# CH564 register map
Vendor: WCH Ltd.; File version: 1.1
Registers are 8-bit, read-write, reset 0x0 unless marked. A register's access mark holds for its fields unless they carry their own. Offsets are from the block's base; [hi:lo] are bit positions.

## UART0
Base 0x4040D000
0x00 R8_UART0_RBR_R8_UART0_THR_R8_UART0_DLL ro — UART0 receiver buffer, receiving byte / UART0 transmitter holding, transmittal byte/DLL is low-byte,DLM is high-byte,together they from the baud rate divisor register
  [7:0] R8_UART0_RBR__R8_UART0_THR_UART0_DLL — UART receiver buffer, receiving byte / UART transmitter holding, transmittal byte
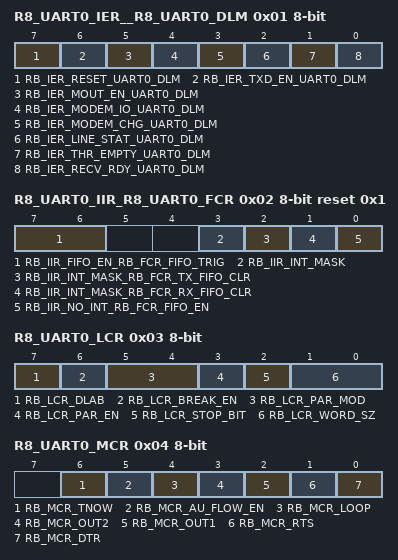
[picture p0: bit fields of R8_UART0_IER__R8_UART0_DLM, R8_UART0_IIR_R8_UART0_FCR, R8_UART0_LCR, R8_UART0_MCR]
0x01 R8_UART0_IER__R8_UART0_DLM — UART0 interrupt enable/baud rate divisor register, DLL is low-byte,DLM is high-byte,together they from the baud rate divisor register
  [7] RB_IER_RESET_UART0_DLM — UART software reset control, high action, auto clear
  [6] RB_IER_TXD_EN_UART0_DLM — UART TXD pin enable
  [5] RB_IER_MOUT_EN_UART0_DLM — UART0 RTS/DTR output pin enable
  [4] RB_IER_MODEM_IO_UART0_DLM — serial modem MODEM signal pin selection bit
  [3] RB_IER_MODEM_CHG_UART0_DLM — UART0 interrupt enable for modem status change
  [2] RB_IER_LINE_STAT_UART0_DLM — UART interrupt enable for receiver line status
  [1] RB_IER_THR_EMPTY_UART0_DLM — UART interrupt enable for THR empty
  [0] RB_IER_RECV_RDY_UART0_DLM — UART interrupt enable for receiver data ready
0x02 R8_UART0_IIR_R8_UART0_FCR ro reset 0x1 — UART0 interrupt identification/FIFO control register
  [7:6] RB_IIR_FIFO_EN_RB_FCR_FIFO_TRIG — UART FIFO enabled flag/UART receiver FIFO trigger level
  [3] RB_IIR_INT_MASK — UART interrupt flag bit mask
  [2] RB_IIR_INT_MASK_RB_FCR_TX_FIFO_CLR — UART interrupt flag bit mask/clear UART transmitter FIFO, high action, auto clear
  [1] RB_IIR_INT_MASK_RB_FCR_RX_FIFO_CLR — UART interrupt flag bit mask/clear UART receiver FIFO, high action, auto clear
  [0] RB_IIR_NO_INT_RB_FCR_FIFO_EN — UART interrupt status flag/FIFO enable bit
0x03 R8_UART0_LCR — UART0 line control
  [7] RB_LCR_DLAB — UART divisor latch access enable bit
  [6] RB_LCR_BREAK_EN — UART break control enable
  [5:4] RB_LCR_PAR_MOD — UART parity mode
  [3] RB_LCR_PAR_EN — UART parity enable
  [2] RB_LCR_STOP_BIT — UART stop bit length
  [1:0] RB_LCR_WORD_SZ — UART word bit length
0x04 R8_UART0_MCR — UART0 modem control
  [6] RB_MCR_TNOW — UART0 enable TNOW output on DTR pin
  [5] RB_MCR_AU_FLOW_EN — UART0 enable autoflow control
  [4] RB_MCR_LOOP — UART0 enable local loop back
  [3] RB_MCR_OUT2 — UART interrupt required output control
  [2] RB_MCR_OUT1 — UART0 MODEM Control bit
  [1] RB_MCR_RTS — UART0 control RTS output
  [0] RB_MCR_DTR — UART0 control DTR output
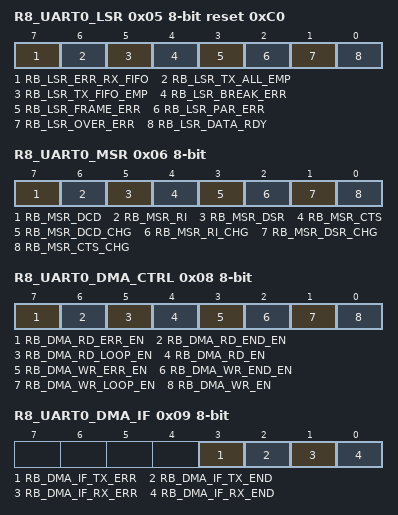
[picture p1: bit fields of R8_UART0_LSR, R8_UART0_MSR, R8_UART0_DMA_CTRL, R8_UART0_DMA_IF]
0x05 R8_UART0_LSR ro reset 0xC0 — UART0 line status
  [7] RB_LSR_ERR_RX_FIFO — indicate error in UART receiver fifo
  [6] RB_LSR_TX_ALL_EMP — UART transmitter all empty status
  [5] RB_LSR_TX_FIFO_EMP — UART transmitter fifo empty status
  [4] RB_LSR_BREAK_ERR — UART receiver break error
  [3] RB_LSR_FRAME_ERR — UART receiver frame error
  [2] RB_LSR_PAR_ERR — UART receiver frame error
  [1] RB_LSR_OVER_ERR — UART receiver overrun error
  [0] RB_LSR_DATA_RDY — UART receiver fifo data ready status
0x06 R8_UART0_MSR ro — UART0 modem status
  [7] RB_MSR_DCD — UART0 DCD action status
  [6] RB_MSR_RI — UART0 RI action status
  [5] RB_MSR_DSR — UART0 DSR action status
  [4] RB_MSR_CTS — UART0 CTS action status
  [3] RB_MSR_DCD_CHG — UART0 DCD changed status, high action
  [2] RB_MSR_RI_CHG — UART0 RI changed status, high action
  [1] RB_MSR_DSR_CHG — UART0 DSR changed status, high action
  [0] RB_MSR_CTS_CHG — UART0 CTS changed status, high action
0x07 R8_UART0_DIV — UART0 pre-frequency divisiono register
  [7:0] UART0_DIV — System clock is pre-divided after frequency doubling to generate the internal reference clock of the serial port
0x08 R8_UART0_DMA_CTRL — DMA Control register
  [7] RB_DMA_RD_ERR_EN — DMA data transfer error interrupt when sending data is enabled
  [6] RB_DMA_RD_END_EN — the end of DMA interrupt when sending data is enabled
  [5] RB_DMA_RD_LOOP_EN — DMA loop mode enabled when sending data
  [4] RB_DMA_RD_EN — DMA enabled when sending data
  [3] RB_DMA_WR_ERR_EN — DMA data transfer error interrupt when receiving data is enabled
  [2] RB_DMA_WR_END_EN — the end of DMA interrupt when receiving data is enabled
  [1] RB_DMA_WR_LOOP_EN — DMA loop mode enabled when receiving data
  [0] RB_DMA_WR_EN — DMA enabled when receiving data
0x09 R8_UART0_DMA_IF — DMA status register
  [3] RB_DMA_IF_TX_ERR — DMA transfer error flag while sending data
  [2] RB_DMA_IF_TX_END — DMA end flag when data is sended
  [1] RB_DMA_IF_RX_ERR — DMA transfer error flag while receiving data
  [0] RB_DMA_IF_RX_END — DMA end flag when data is received
0x0C R32_UART0_DMA_WR_NOW_ADDR 32-bit ro — DMA receive mode current address register
  [17:0] DMA_WR_NOW_ADDR — DMA receive mode current address
0x10 R32_UART0_DMA_WR_START_ADDR 32-bit — DMA receive mode start address register
  [17:0] DMA_WR_START_ADDR — DMA receive mode start address
0x14 R32_UART0_DMA_WR_END_ADDR 32-bit — DMA received mode end address register
  [17:0] DMA_WR_END_ADDR — DMA receivek mode end address
0x18 R32_UART0_DMA_RD_NOW_ADDR 32-bit ro — DMA send mode current address register
  [17:0] DMA_WR_RD_ADDR — DMA send mode current address
0x1C R32_UART0_DMA_RD_START_ADDR 32-bit — DMA send mode start address register
  [17:0] DMA_RD_START_ADDR — DMA send mode start address
0x20 R32_UART0_DMA_RD_END_ADDR 32-bit — DMA send mode end address register
  [17:0] DMA_RD_END_ADDR — DMA send mode end address

## UART1
Base 0x4040D800
Same registers: UART2 0x40409000, UART3 0x40409800
Registers as UART0 (with UART0 read as UART1), without R8_UART0_IER__R8_UART0_DLM; these are added or differ:
0x00 R8_UART1_RBR_R8_UART1_THR_R8_UART1_DLL ro — UART1 receiver buffer, receiving byte / UART1 transmitter holding, transmittal byte/DLL is low-byte,DLM is high-byte,together they from the baud rate divisor register
  [7:0] R8_UART1_RBR_R8_UART1_THR_UART1_DLL — UART receiver buffer, receiving byte / UART transmitter holding, transmittal byte
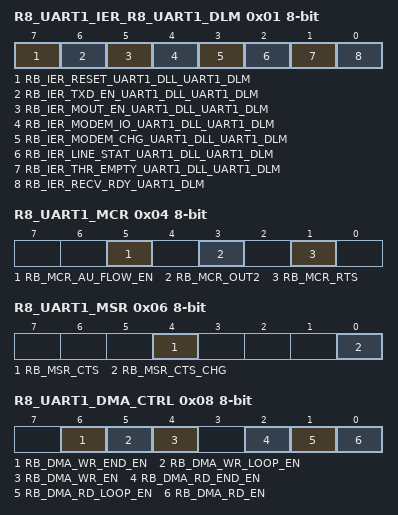
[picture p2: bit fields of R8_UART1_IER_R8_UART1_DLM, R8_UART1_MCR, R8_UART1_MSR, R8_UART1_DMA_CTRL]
0x01 R8_UART1_IER_R8_UART1_DLM — UART1 interrupt enable/baud rate divisor register, DLL is low-byte,DLM is high-byte,together they from the baud rate divisor register
  [7] RB_IER_RESET_UART1_DLL_UART1_DLM — UART software reset control, high action, auto clear
  [6] RB_IER_TXD_EN_UART1_DLL_UART1_DLM — UART TXD pin enable
  [5] RB_IER_MOUT_EN_UART1_DLL_UART1_DLM — UART1 RTS/DTR output pin enable
  [4] RB_IER_MODEM_IO_UART1_DLL_UART1_DLM — serial modem MODEM signal pin selection bit
  [3] RB_IER_MODEM_CHG_UART1_DLL_UART1_DLM — UART1 interrupt enable for modem status change
  [2] RB_IER_LINE_STAT_UART1_DLL_UART1_DLM — UART interrupt enable for receiver line status
  [1] RB_IER_THR_EMPTY_UART1_DLL_UART1_DLM — UART interrupt enable for THR empty
  [0] RB_IER_RECV_RDY_UART1_DLM — UART interrupt enable for receiver data ready
0x04 R8_UART1_MCR — UART1 modem control
  [5] RB_MCR_AU_FLOW_EN — UART1 enable autoflow control
  [3] RB_MCR_OUT2 — UART interrupt required output control
  [1] RB_MCR_RTS — UART1 control RTS output
0x06 R8_UART1_MSR ro — UART1 modem status
  [4] RB_MSR_CTS — UART1 CTS action status
  [0] RB_MSR_CTS_CHG — UART1 CTS changed status, high action
0x08 R8_UART1_DMA_CTRL — DMA Control register
  [6] RB_DMA_WR_END_EN — the end of DMA interrupt when sending data is enabled
  [5] RB_DMA_WR_LOOP_EN — DMA loop mode enabled when sending data
  [4] RB_DMA_WR_EN — DMA enabled when sending data
  [2] RB_DMA_RD_END_EN — the end of DMA interrupt when receiving data is enabled
  [1] RB_DMA_RD_LOOP_EN — DMA loop mode enabled when receiving data
  [0] RB_DMA_RD_EN — DMA enabled when receiving data
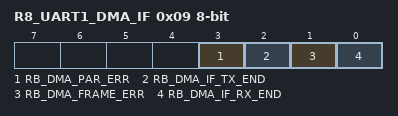
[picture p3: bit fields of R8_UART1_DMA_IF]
0x09 R8_UART1_DMA_IF — DMA status register
  [3] RB_DMA_PAR_ERR — PARITY error flag bit in DMA mode
  [2] RB_DMA_IF_TX_END — DMA end flag when data is sended
  [1] RB_DMA_FRAME_ERR — FRAME error flag bit in DMA mode
  [0] RB_DMA_IF_RX_END — DMA end flag when data is received
